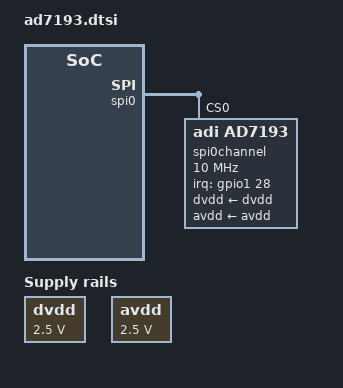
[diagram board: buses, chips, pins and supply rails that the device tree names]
// overlay for ad7193 adc on spi0
#include "subarctic/pinctrl.h"
#include "bone/pins.h"
#include "irq.h"

// disable conflicting cape-universal nodes
USES_PIN( P9_17 );  // cs 0
USES_PIN( P9_18 );  // data out
USES_PIN( P9_21 );  // data in
USES_PIN( P9_22 );  // clk
USES_PIN( P9_12 );  // irq

// XXX apparently this doesn't work
//&spi0 {
//	spi0channel@0 {  status = "disabled";  };
//	spi0channel@1 {  status = "disabled";  };
//};

&spi0 {
	pinctrl-names = "default";
	pinctrl-0 = <&spi0_pins>;
	ti,spi-num-cs = <1>;
	status = "okay";
};

&am33xx_pinmux {
	spi0_pins: spi0 {
		pinctrl-single,pins = <
			PIN_IO_PULLUP(  P9_22, 0 )  // clk
			PIN_IN_PULLUP(  P9_21, 0 )  // data in
			PIN_OUT_PULLUP( P9_18, 0 )  // data out
			PIN_OUT_PULLUP( P9_17, 0 )  // cs 0
		>;
	};
};

//rdy_irq_pin: phandle label
//ad7193: should be unique within &am33xx_pinmux
&am33xx_pinmux {
	rdy_irq_pin: ad7193 {
		pinctrl-single,pins = <
			PIN_GPIN_PULLUP( P9_12 )
		>;
	};
};

/{
	dvdd: dvdd-vref {
		compatible = "regulator-fixed";
		regulator-name = "dvdd_vref";
		regulator-min-microvolt = <2500000>;
		regulator-max-microvolt = <2500000>;
		regulator-boot-on;
	};
};

/{
	avdd: avdd-vref {
		compatible = "regulator-fixed";
		regulator-name = "avdd_vref";
		regulator-min-microvolt = <2500000>;
		regulator-max-microvolt = <2500000>;
		regulator-boot-on;
	};
};

&spi0 {
	// XXX for now, use same names as cape-universal for compatibility
	spi0channel@0 {
		reg = <0>;
		compatible = "adi,ad7193";
		spi-max-frequency = <10000000>;
		spi-cpol;
		spi-cpha;
		dvdd-supply = <&dvdd>;
		avdd-supply = <&avdd>;
		interrupt-parent = <&gpio1>;
		interrupts = <28 IRQ_TYPE_EDGE_FALLING>;
		status = "okay";
	};
};
